# R7KA8M2AD register map
Vendor: Renesas Electronics Corporation; Series: RA8; File version: 1.10.02
CPU: CM85 r0p2, little endian, MPU, FPU, VTOR, 4 interrupt priority bits, 96 interrupts
Registers are 32-bit, read-write, reset 0x0 unless marked. A register's access mark holds for its fields unless they carry their own. Offsets are from the block's base; [hi:lo] are bit positions; {n}, {i} and the like mark numbered series; 'fields as' and 'values as' point back to an identical list.

## COMA — Common Agent
Base 0x403C9000
Same registers: COMA_NS 0x503C9000
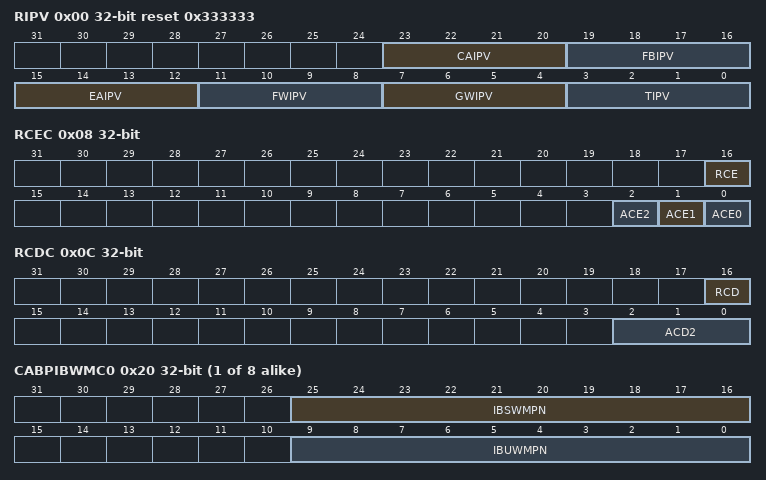
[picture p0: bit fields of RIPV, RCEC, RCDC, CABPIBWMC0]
0x00 RIPV ro reset 0x333333 — IP Version Register
  [23:20] CAIPV — Ethernet Common Agent IP Version Number
  [19:16] FBIPV — Fabric Bus IP Version Number
  [15:12] EAIPV — Ethernet Agent IP Version Number
  [11:8] FWIPV — Forwarding Engine IP Version Number
  [7:4] GWIPV — Gateway CPU Agent IP Version Number
  [3:0] TIPV — Top Module IP Version Number
0x04 RRC — Reset Configuration Register
  [0] RR — Software Reset
    0=ESWM not reset; 1=ESWM reset
0x08 RCEC — Clock Enable Configuration Register
  [16] RCE — Clock Enable
    0=ESWM clock disabled; 1=ESWM clock enabled
  [2] ACE2 — Agent i Clock Enable (i = 0 to 2)
    0=Agent i clock disabled; 1=Agent i clock enabled
  [1] ACE1 — Agent i Clock Enable (i = 0 to 2)
    0=Agent i clock disabled; 1=Agent i clock enabled
  [0] ACE0 — Agent i Clock Enable (i = 0 to 2)
    0=Agent i clock disabled; 1=Agent i clock enabled
0x0C RCDC — Clock Disable Configuration Register
  [16] RCD wo — Clock Disable
  [2:0] ACD2 to ACD0 wo — Agent i Clock Disable (i = 0 to 2)
    0=No effect; 1=Clears bit i in RCEC.ACEi register
{0x20+4i} CABPIBWMC{i} (i=0..7) — Buffer Pool IPV Based Watermark Configuration Register {i}
  [25:16] IBSWMPN — IPV Based Secure Watermark Pointer Number
  [9:0] IBUWMPN — IPV Based Unsecure Watermark Pointer Number
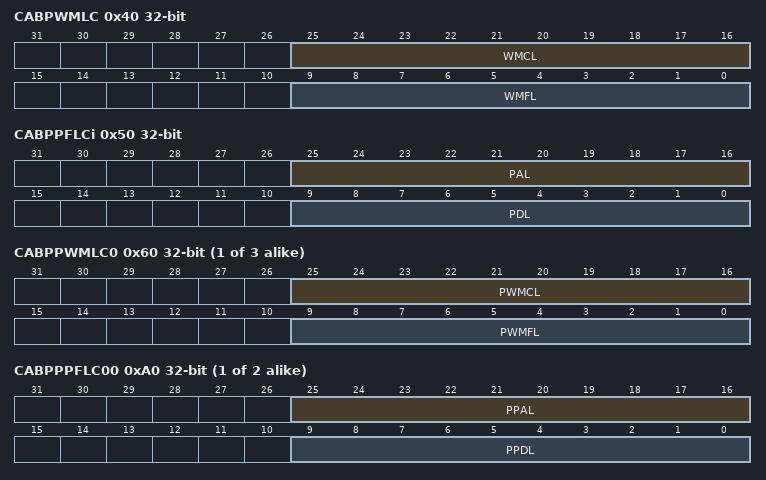
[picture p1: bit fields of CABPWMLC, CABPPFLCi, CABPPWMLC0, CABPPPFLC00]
0x40 CABPWMLC — Buffer Pool Watermark Level Configuration Register
  [25:16] WMCL — Watermark Critical Level
  [9:0] WMFL — Watermark Flush Level
0x50 CABPPFLCi — Buffer Pointer Pause Frame Level i Configuration Register
  [25:16] PAL — Pause Assertion Level
  [9:0] PDL — Pause De-Assertion Level
{0x60+4i} CABPPWMLC{i} (i=0..2) — Port {i} Buffer Pool Watermark Level Configuration Register
  [25:16] PWMCL — Watermark Critical Level
  [9:0] PWMFL — Watermark Flush Level
{0xA0+4i} CABPPPFLC0{i} (i=0..1) — Port i Buffer Pointer Pause Frame Level {i} Configuration Register
  [25:16] PPAL — Pause Assertion Level
  [9:0] PPDL — Pause De-Assertion Level
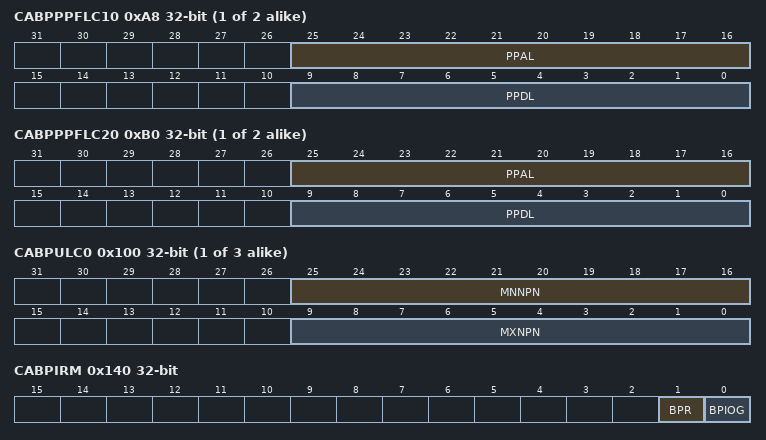
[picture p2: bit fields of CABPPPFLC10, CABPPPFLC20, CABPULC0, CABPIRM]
{0xA8+4i} CABPPPFLC1{i} (i=0..1) — Port i Buffer Pointer Pause Frame Level {i} Configuration Register
  fields as CABPPPFLC00
{0xB0+4i} CABPPPFLC2{i} (i=0..1) — Port i Buffer Pointer Pause Frame Level {i} Configuration Register
  fields as CABPPPFLC00
{0x100+4i} CABPULC{i} (i=0..2) — Port {i} Buffer Pointer Utilization Level Configuration Register i
  [25:16] MNNPN — Minimum Number of Pointer
  [9:0] MXNPN — Maximum Number of Pointer
0x140 CABPIRM — Buffer Pool Initialization Register Monitoring Register
  [1] BPR — Buffer Pool Ready
  [0] BPIOG — Buffer Pool Initialization Ongoing
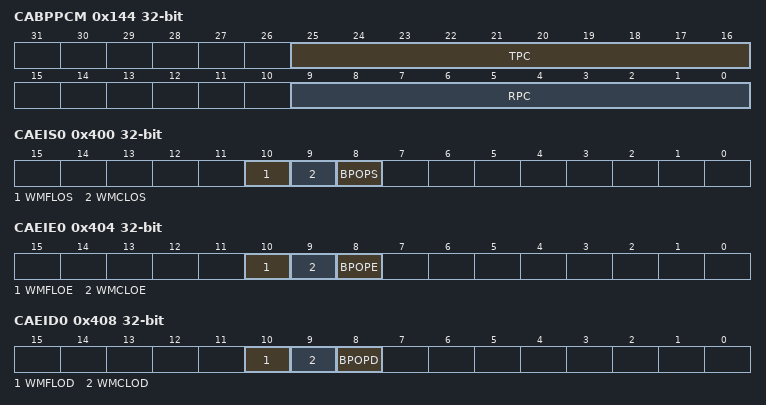
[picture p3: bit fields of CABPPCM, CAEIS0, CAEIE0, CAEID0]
0x144 CABPPCM ro — Buffer Pool Pointer Count Monitoring Register
  [25:16] TPC — Total Pointer Count
  [9:0] RPC — Remaining Pointer Count
0x148 CABPLCM ro — Buffer Pool Pointer Least Count Monitoring Register
  [12:0] LRC — Least Remaining Pointer Count
{0x180+4i} CABPCPM{i} (i=0..2) ro — Port {i} Buffer Pointer Count Monitoring Register
  [12:0] RPCP — Received Pointer Count
{0x200+4i} CABPMCPM{i} (i=0..2) ro — Port {i} Buffer Pointer Maximum Count Monitoring Register
  [12:0] RPMCP — Received Pointer Maximum Count
0x300 CARDNM ro — Rejected Descriptor Number Monitoring Register
  [12:0] RDNRR — Rejected Descriptor Number in Reject RAM
0x304 CARDMNM ro — Rejected Descriptor Maximum Number Monitoring Register
  [12:0] RDMNRR — Rejected Descriptor Maximum Number in Reject RAM
0x310 CARDCN ro — Rejected Descriptor Counter Register
  [31:0] RDN — Rejected Descriptor Number
0x400 CAEIS0 — Error Interrupt Status Register 0
  [10] WMFLOS — Watermark Flush Level Overtook Status Flag
  [9] WMCLOS — Watermark Critical Level Overtook Status Flag
  [8] BPOPS — Buffer Pool Out of Pointer Status Flag
0x404 CAEIE0 — Error Interrupt Enable Register 0
  [10] WMFLOE — Watermark Flush Level Overtook Enable
  [9] WMCLOE — Watermark Critical Level Overtook Enable
  [8] BPOPE — Buffer Pool Out of Pointer Enable
0x408 CAEID0 ro — Error Interrupt Disable Register 0
  [10] WMFLOD — Watermark Flush Level Overtook Disable
  [9] WMCLOD — Watermark Critical Level Overtook Disable
  [8] BPOPD — Buffer Pool Out of Pointer Disable
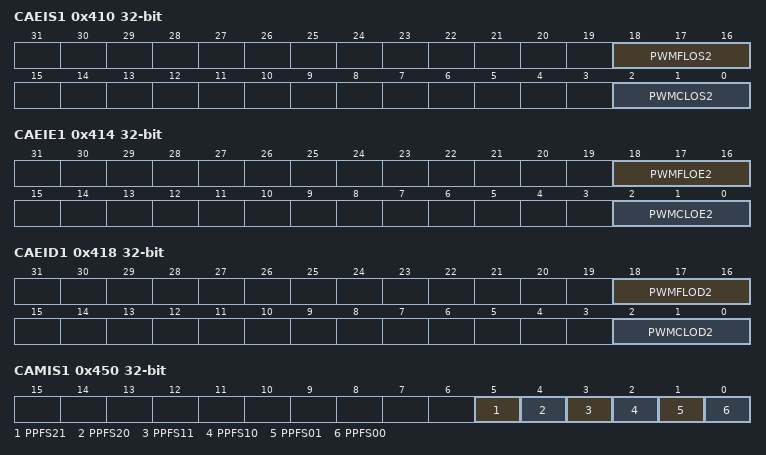
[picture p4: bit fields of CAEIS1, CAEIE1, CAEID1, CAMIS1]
0x410 CAEIS1 — Error Interrupt Status Register 1
  [18:16] PWMFLOS2 to PWMFLOS0 — Port n Watermark Flush Level Overtook Status Flag (n = 0 to 2)
  [2:0] PWMCLOS2 to PWMCLOS0 — Port n Watermark Critical Level Overtook Status Flag (n = 0 to 2)
0x414 CAEIE1 — Error Interrupt Enable Register 1
  [18:16] PWMFLOE2 to PWMFLOE0 — Port n Watermark Flush Level Overtook Enable (n = 0 to 2)
  [2:0] PWMCLOE2 to PWMCLOE0 — Port n Watermark Critical Level Overtook Enable (n = 0 to 2)
0x418 CAEID1 ro — Error Interrupt Disable Register 1
  [18:16] PWMFLOD2 to PWMFLOD0 — Port n Watermark Flush Level Overtook Disable (n = 0 to 2)
  [2:0] PWMCLOD2 to PWMCLOD0 — Port n Watermark Critical Level Overtook Disable (n = 0 to 2)
0x440 CAMIS0 — Monitoring Interrupt Status Register 0
  [1:0] PFS1 to PFS0 — Pause Frame Status Flag n (n= 0 to 1)
0x444 CAMIE0 — Monitoring Interrupt Enable Register 0
  [1:0] PFE1 to PFE0 — Pause Frame Enable n (n = 0 to 1)
0x448 CAMID0 ro — Monitoring Interrupt Disable Register 0
  [1:0] PFD1 to PFD0 — Pause Frame Disable n (n = 0 to 1)
0x450 CAMIS1 — Monitoring Interrupt Status Register 1
  [5] PPFS21 — Port 2 Pause Frame Status Flag 1
  [4] PPFS20 — Port 2 Pause Frame Status Flag 0
  [3] PPFS11 — Port 1 Pause Frame Status Flag 1
  [2] PPFS10 — Port 1 Pause Frame Status Flag 0
  [1] PPFS01 — Port 0 Pause Frame Status Flag 1
  [0] PPFS00 — Port 0 Pause Frame Status Flag 0
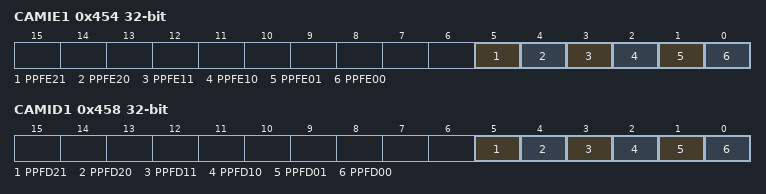
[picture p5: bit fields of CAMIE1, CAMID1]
0x454 CAMIE1 — Monitoring Interrupt Enable Register 1
  [5] PPFE21 — Port 2 Pause Frame Enable 1
  [4] PPFE20 — Port 2 Pause Frame Enable 0
  [3] PPFE11 — Port 1 Pause Frame Enable 1
  [2] PPFE10 — Port 1 Pause Frame Enable 0
  [1] PPFE01 — Port 0 Pause Frame Enable 1
  [0] PPFE00 — Port 0 Pause Frame Enable 0
0x458 CAMID1 — Monitoring Interrupt Disable Register 1
  [5] PPFD21 wo — Port 2 Pause Frame Disable 1
  [4] PPFD20 wo — Port 2 Pause Frame Disable 0
  [3] PPFD11 wo — Port 1 Pause Frame Disable 1
  [2] PPFD10 wo — Port 1 Pause Frame Disable 0
  [1] PPFD01 wo — Port 0 Pause Frame Disable 1
  [0] PPFD00 wo — Port 0 Pause Frame Disable 0
